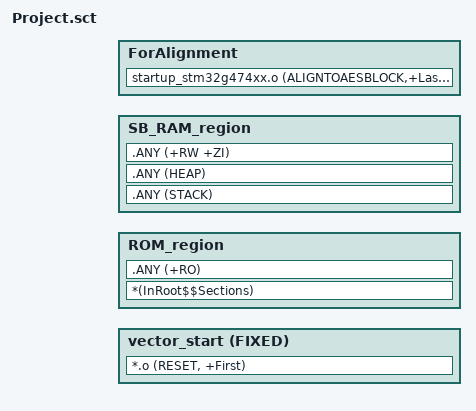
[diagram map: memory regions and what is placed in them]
#! armclang --target=arm-arm-none-eabi  -mcpu=cortex-m4 -E -xc
; *************************************************************
; *** Scatter-Loading Description File generated by uVision ***
; *************************************************************
#include "..\..\Linker_Common\MDK-ARM\mapping_sbsfu.h"
#include "..\..\Linker_Common\MDK-ARM\mapping_fwimg.h"


0R_ROM (SLOT_ACTIVE_1_START + 0x1000) {                      ; 0x1000 = IMAGE_OFFSET
  vector_start (SLOT_ACTIVE_1_START + 0x1000) FIXED VECTOR_SIZE {
  *.o (RESET, +First)
  }
  ROM_region +0 {
  *(InRoot$$Sections)
  .ANY (+RO)
  }
  SB_RAM_region (SE_REGION_RAM_END + 1) {
  .ANY (STACK)
  .ANY (HEAP)
  .ANY (+RW +ZI)
  }
}

; extra ROM region to make sure the binary size is a multiple of the AES block size (16 bytes) and G4 flash writing unit (8 bytes)
LR_ROM1(+0) ALIGN(16) {
  ForAlignment +0 {
    startup_stm32g474xx.o (ALIGNTOAESBLOCK,+Last)
  }
}
